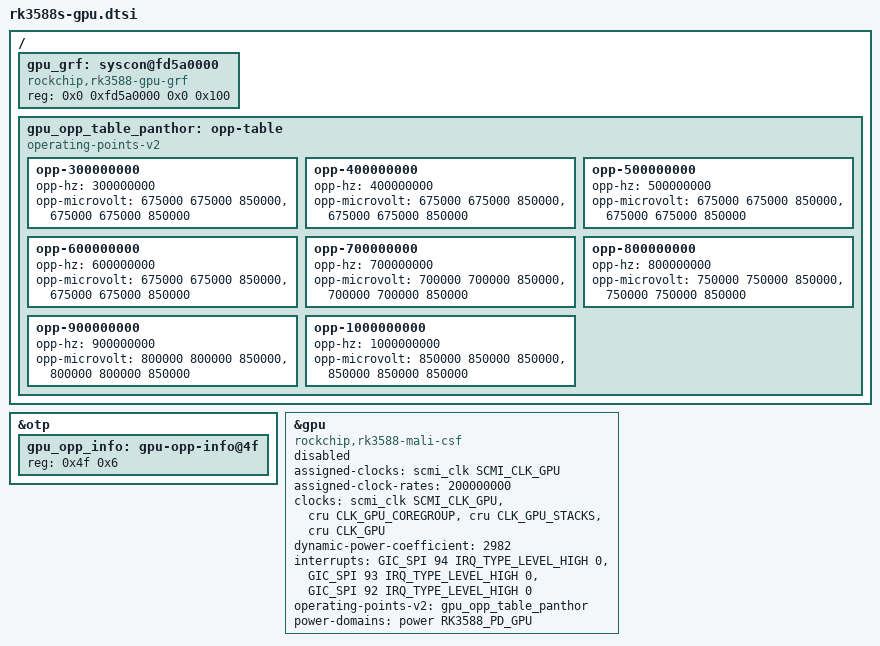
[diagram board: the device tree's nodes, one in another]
/*
 * Copyright (c) 2021 Rockchip Electronics Co., Ltd.
 * Copyright (c) 2025 jjm2473 <jjm2473@gmail.com>
 *
 * Fix: 不删除 gpu 节点，直接修改其属性，保留标签兼容性
 * RK3588 GPU 为 Valhall 架构，兼容 panthor 驱动
 */

&otp {
	gpu_opp_info: gpu-opp-info@4f {
		reg = <0x4f 0x6>;
	};
};

/ {
	gpu_grf: syscon@fd5a0000 {
		compatible = "rockchip,rk3588-gpu-grf", "syscon";
		reg = <0x0 0xfd5a0000 0x0 0x100>;
	};

	gpu_opp_table_panthor: opp-table {
		compatible = "operating-points-v2";

		opp-300000000 {
			opp-hz = /bits/ 64 <300000000>;
			opp-microvolt = <675000 675000 850000>, <675000 675000 850000>;
		};
		opp-400000000 {
			opp-hz = /bits/ 64 <400000000>;
			opp-microvolt = <675000 675000 850000>, <675000 675000 850000>;
		};
		opp-500000000 {
			opp-hz = /bits/ 64 <500000000>;
			opp-microvolt = <675000 675000 850000>, <675000 675000 850000>;
		};
		opp-600000000 {
			opp-hz = /bits/ 64 <600000000>;
			opp-microvolt = <675000 675000 850000>, <675000 675000 850000>;
		};
		opp-700000000 {
			opp-hz = /bits/ 64 <700000000>;
			opp-microvolt = <700000 700000 850000>, <700000 700000 850000>;
		};
		opp-800000000 {
			opp-hz = /bits/ 64 <800000000>;
			opp-microvolt = <750000 750000 850000>, <750000 750000 850000>;
		};
		opp-900000000 {
			opp-hz = /bits/ 64 <900000000>;
			opp-microvolt = <800000 800000 850000>, <800000 800000 850000>;
		};
		opp-1000000000 {
			opp-hz = /bits/ 64 <1000000000>;
			opp-microvolt = <850000 850000 850000>, <850000 850000 850000>;
		};
	};
};

/* 修改原有的 gpu 节点以使用 Valhall 架构驱动 */
&gpu {
	compatible = "rockchip,rk3588-mali-csf", "arm,mali-valhall";
	#cooling-cells = <2>;
	assigned-clocks = <&scmi_clk SCMI_CLK_GPU>;
	assigned-clock-rates = <200000000>;
	clocks = <&scmi_clk SCMI_CLK_GPU>, <&cru CLK_GPU_COREGROUP>,
		 <&cru CLK_GPU_STACKS>, <&cru CLK_GPU>;
	clock-names = "clk_mali", "clk_gpu_coregroup",
		      "clk_gpu_stacks", "clk_gpu";
	dynamic-power-coefficient = <2982>;
	interrupts = <GIC_SPI 94 IRQ_TYPE_LEVEL_HIGH 0>,
		     <GIC_SPI 93 IRQ_TYPE_LEVEL_HIGH 0>,
		     <GIC_SPI 92 IRQ_TYPE_LEVEL_HIGH 0>;
	interrupt-names = "GPU", "MMU", "JOB";
	operating-points-v2 = <&gpu_opp_table_panthor>;
	power-domains = <&power RK3588_PD_GPU>;
	status = "disabled";
};


